# MSS_CCMR register map
Vendor: Texas Instruments
Peripheral module from a debugger description file (folder awr29xx).
Registers are 32-bit, read-write, no defined reset value unless marked. A register's access mark holds for its fields unless they carry their own. Offsets are as the file gives them; lines under a group give offsets from that group; [hi:lo] are bit positions; {n}, {i} and the like mark numbered series; 'fields as' and 'values as' point back to an identical list; <NAME> marks a mode.

## MSS_CCMR
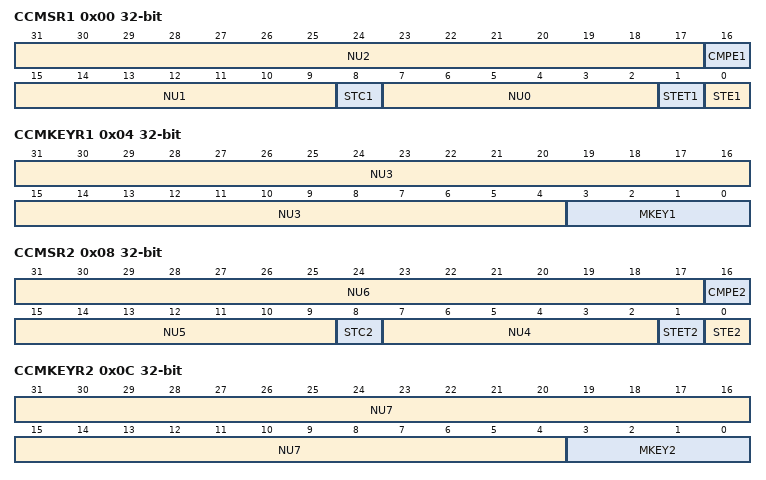
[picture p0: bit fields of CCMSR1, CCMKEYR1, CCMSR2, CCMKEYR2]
0x00 CCMSR1 access per field — CPU Compare Status Register
  [31:17] NU2 rw — Reserved
  [16] CMPE1 rw — Compare Error 0 = CPU signals are identical 1= CPU signal compare mismatch Writes '1' to clear this bit
  [15:9] NU1 rw — Reserved
  [8] STC1 rw — Self Test Complete 0 = self test on-going if self test mode asserted 1 = self test is complete Writes have no effect
  [7:2] NU0 rw — Reserved
  [1] STET1 rw — Self Test Error Type 0 = self test failed during Compare Match test 1 = self test failed during Compare mismatch test Writes have no effect
  [0] STE1 ro — Self Test Error 0 = self test passed 1 = self test failed Writes have no effect
0x04 CCMKEYR1 — CPU Compare Key Register
  [31:4] NU3 — Reserved
  [3:0] MKEY1 — Mode Key 0000 = lock step mode 0110 = self test mode 1001 = error forcing mode 1111 = self test error forcing mode
0x08 CCMSR2 — VIM Compare Status Register
  [31:17] NU6 — Reserved
  [16] CMPE2 — Compare Error 0 = VIM signals are identical 1= VIM signal compare mismatch Writes '1' to clear this bit
  [15:9] NU5 — Reserved
  [8] STC2 — Self Test Complete 0 = self test on-going if self test mode asserted 1 = self test is complete Writes have no effect
  [7:2] NU4 — Reserved
  [1] STET2 — Self Test Error Type 0 = self test failed during Compare Match test 1 = self test failed during Compare mismatch test Writes have no effect
  [0] STE2 — Self Test Error 0 = self test passed 1 = self test failed Writes have no effect
0x0C CCMKEYR2 — VIM Compare Key Register
  [31:4] NU7 — Reserved
  [3:0] MKEY2 — Mode Key 0000 = lock step mode 0110 = self test mode 1001 = error forcing mode 1111 = self test error forcing mode
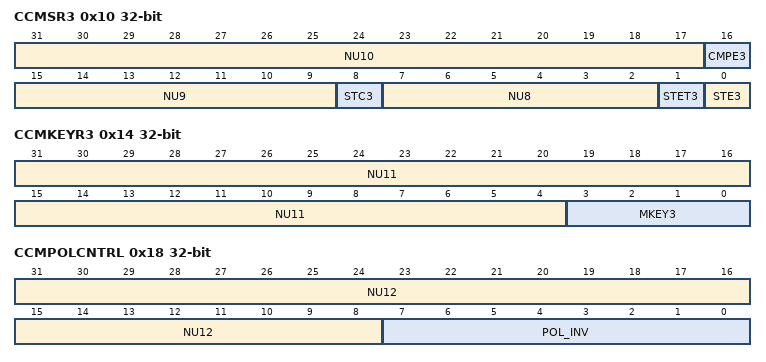
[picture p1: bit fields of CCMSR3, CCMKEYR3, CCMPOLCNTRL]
0x10 CCMSR3 access per field — Inactivity Monitor Status Register
  [31:17] NU10 rw — Reserved
  [16] CMPE3 rw — Compare Error 0 = Inactivity monitor signals are identical 1= Inactivity monitor signal compare mismatch Writes '1' to clear this bit
  [15:9] NU9 rw — Reserved
  [8] STC3 rw — Self Test Complete 0 = self test on-going if self test mode asserted 1 = self test is complete Writes have no effect
  [7:2] NU8 rw — Reserved
  [1] STET3 rw — Self Test Error Type 0 = self test failed during Compare Match test 1 = self test failed during Compare mismatch test Writes have no effect
  [0] STE3 ro — Self Test Error 0 = self test passed 1 = self test failed Writes have no effect
0x14 CCMKEYR3 — Inactivity Monitor Key Register
  [31:4] NU11 — Reserved
  [3:0] MKEY3 — Mode Key 0000 = lock step mode 0110 = self test mode 1001 = error forcing mode 1111 = self test error forcing mode
0x18 CCMPOLCNTRL access per field — CPU Compare Polarity Control Register
  [31:8] NU12 rw — Reserved
  [7:0] POL_INV ro — This value is used to invert the 8 XOR of the CPU1 to create compare fail in functional active compare mode. User and privilege mode read = Returns current value of the POL INV Privilege mode write = Update the values of POL INV
